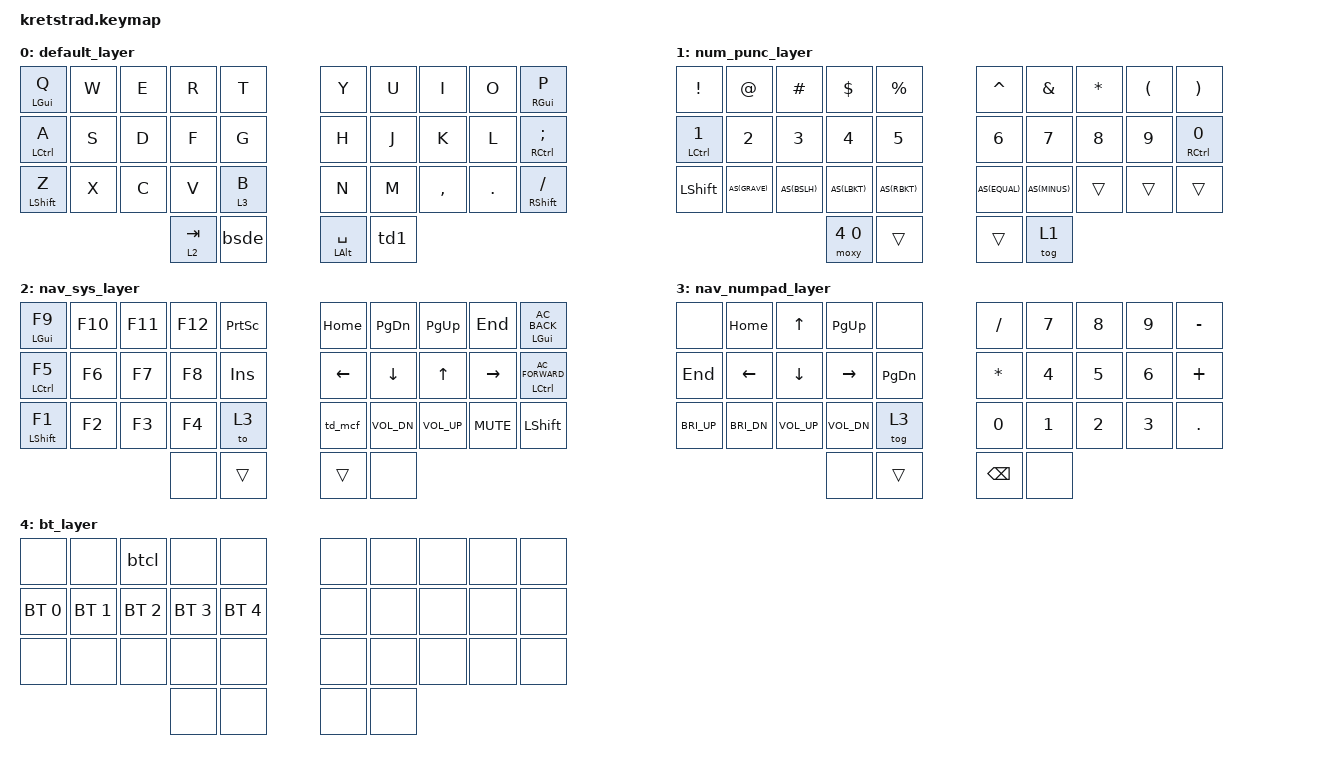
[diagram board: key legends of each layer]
/*
 * Copyright (c) 2020 The ZMK Contributors
 *
 * SPDX-License-Identifier: MIT
 */

#include <behaviors.dtsi>
#include <dt-bindings/zmk/keys.h>
#include <dt-bindings/zmk/bt.h>
#include <dt-bindings/zmk/mouse.h>

#define AS(keycode) &as keycode keycode     // Autoshift Macro
#define MB(keycode) &mbl keycode keycode    // Normal and sticky mouse key Macro

&sl {
    release-after-ms = <500>;
    /delete-property/ quick-release;
};

/ {

    macros {
        moxy: mo_to_x_back_to_y {
            compatible = "zmk,behavior-macro-two-param";
            #binding-cells = <2>;
            wait-ms = <0>;
            tap-ms = <0>;
            bindings
                = <&macro_param_1to1>
                , <&macro_press &mo MACRO_PLACEHOLDER>
                , <&macro_pause_for_release>
                , <&macro_param_1to1>
                , <&macro_release &mo MACRO_PLACEHOLDER>
                , <&macro_param_2to1>
                , <&macro_tap &to MACRO_PLACEHOLDER>
                ;
        };

        as_s: autoshift_single {
            compatible = "zmk,behavior-macro-one-param";
            #binding-cells = <1>;
            wait-ms = <0>;
            tap-ms = <0>;
            bindings
                = <&macro_press &kp LSHFT>
                , <&macro_param_1to1>
                , <&macro_tap &kp MACRO_PLACEHOLDER>
                , <&macro_release &kp LSHFT>
                ;
        };

    };

    behaviors {
        ht: hold_tap_standard {
            compatible = "zmk,behavior-hold-tap";
            #binding-cells = <2>;
            tapping-term-ms = <175>;
            quick-tap-ms = <250>;
            flavor = "tap-preferred";
            bindings = <&kp>, <&kp>;
        };

        hl: hold_tap_long {
            compatible = "zmk,behavior-hold-tap";
            #binding-cells = <2>;
            tapping-term-ms = <200>;
            quick-tap-ms = <250>;
            flavor = "tap-preferred";
            bindings = <&kp>, <&kp>;
        };

        hs: hold_tap_short {
            compatible = "zmk,behavior-hold-tap";
            #binding-cells = <2>;
            tapping-term-ms = <150>;
            quick-tap-ms = <250>;
            flavor = "tap-preferred";
            bindings = <&kp>, <&kp>;
        };

        hss: hold_tap_super_short {
            compatible = "zmk,behavior-hold-tap";
            #binding-cells = <2>;
            tapping-term-ms = <110>;
            quick-tap-ms = <250>;
            flavor = "tap-preferred";
            bindings = <&kp>, <&kp>;
        };

        pk: hold_tap_pinky {
            compatible = "zmk,behavior-hold-tap";
            #binding-cells = <2>;
            tapping-term-ms = <125>;
            quick-tap-ms = <250>;
            flavor = "tap-preferred";
            bindings = <&kp>, <&kp>;
        };

        mbl: mouse_button_long_press  {
            compatible = "zmk,behavior-hold-tap";
            #binding-cells = <2>;
            tapping_term_ms = <500>;
            flavor = "tap-preferred";
            bindings = <&skmk>, <&mkp>;
        };

        as: auto_shift_key  {
            compatible = "zmk,behavior-hold-tap";
            #binding-cells = <2>;
            tapping_term_ms = <225>;
            flavor = "tap-preferred";
            bindings = <&as_s>, <&kp>;
        };

        lh: layer_tap_hold_pref {
            compatible = "zmk,behavior-hold-tap";
            #binding-cells = <2>;
            tapping_term_ms = <150>;
            flavor = "hold-preferred";
            bindings = <&mo>, <&kp>;
        };

        bsde: backspace_delete {
            compatible = "zmk,behavior-mod-morph";
            #binding-cells = <0>;
            bindings = <&hss LALT BSPC>, <&kp DELETE>;
            mods = <(MOD_LSFT|MOD_RSFT)>;
            /* keep-mods = <(MOD_RSFT)>; */
        };

        td1: tap_dance_layer_1 {
            compatible = "zmk,behavior-tap-dance";
            #binding-cells = <0>;
            tapping-term-ms = <250>;
            bindings = <&sl 1>, <&to 1>;
        };

        td_mc: tap_dance_media_control {
            compatible = "zmk,behavior-tap-dance";
            #binding-cells = <0>;
            tapping-term-ms = <250>;
            bindings = <&kp C_NEXT>, <&kp C_PREV>;
        };

        td_mcf: tap_dance_media_control_full {
            compatible = "zmk,behavior-tap-dance";
            #binding-cells = <0>;
            tapping-term-ms = <250>;
            bindings = <&kp C_PP>, <&kp C_NEXT>, <&kp C_PREV>;
        };

        btcl: bluetooth_clear_double_tap {
            compatible = "zmk,behavior-tap-dance";
            #binding-cells = <0>;
            tapping-term-ms = <250>;
            bindings = <&none>, <&bt BT_CLR>;
        };

        skmk: sticky_mouse_key {
            compatible = "zmk,behavior-sticky-key";
            #binding-cells = <1>;
            bindings = <&mkp>;
            release-after-ms = <5000>;
            quick-release;
        };

    };

    keymap {
        compatible = "zmk,keymap";

        default_layer {
            bindings = <
                &hl LGUI Q   &kp W  &kp E  &kp R      &kp T        &kp Y            &kp U  &kp I      &kp O    &ht RGUI P
                &hl LCTRL A  &kp S  &kp D  &kp F      &kp G        &kp H            &kp J  &kp K      &kp L    &ht RCTRL SEMI
                &pk LSHFT Z  &kp X  &kp C  &kp V      &lt 3 B      &kp N            &kp M  &kp COMMA  &kp DOT  &pk RSHFT FSLH
                                           &lh 2 TAB  &bsde        &hs LALT SPACE   &td1
                >;
        };

        // Numbers and punctuations each on separate row
        num_punc_layer {
            bindings = <
                &kp EXCL      &kp AT     &kp HASH  &kp DLLR   &kp PRCNT      &kp CARET  &kp AMPS   &kp STAR  &kp LPAR  &kp RPAR
                &hl LCTRL N1  &kp N2     &kp N3    &kp N4     &kp N5         &kp N6     &kp N7     &kp N8    &kp N9    &ht RCTRL N0
                &kp LSHFT     AS(GRAVE)  AS(BSLH)  AS(LBKT)   AS(RBKT)       AS(EQUAL)  AS(MINUS)  &trans    &trans    &trans
                                                   &moxy 4 0  &trans         &trans     &tog 1
                >;
        };

        nav_sys_layer {
            bindings = <
                &ht LGUI F9   &kp F10  &kp F11  &kp F12  &kp PSCRN      &kp HOME  &kp PG_DN     &kp PG_UP     &kp END     &ht LGUI C_AC_BACK
                &ht LCTRL F5  &kp F6   &kp F7   &kp F8   &kp INS        &kp LEFT  &kp DOWN      &kp UP        &kp RIGHT   &ht LCTRL C_AC_FORWARD
                &ht LSHFT F1  &kp F2   &kp F3   &kp F4   &to 3          &td_mcf   &kp C_VOL_DN  &kp C_VOL_UP  &kp C_MUTE  &kp LSHFT
                                                &none    &trans         &trans    &none
                >;
        };

        nav_numpad_layer {
            bindings = <
                &none         &kp HOME     &kp UP        &kp PG_UP     &none          &kp FSLH  &kp N7  &kp N8  &kp N9  &kp MINUS
                &kp END       &kp LEFT     &kp DOWN      &kp RIGHT     &kp PG_DN      &kp STAR  &kp N4  &kp N5  &kp N6  &kp PLUS
                &kp C_BRI_UP  &kp C_BRI_DN &kp C_VOL_UP  &kp C_VOL_DN  &tog 3         &kp N0    &kp N1  &kp N2  &kp N3  &kp DOT
                                                         &none         &trans         &kp BSPC  &none
                >;
        };

        bt_layer {
            bindings = <
                &none         &none         &btcl         &none         &none             &none   &none   &none  &none  &none
                &bt BT_SEL 0  &bt BT_SEL 1  &bt BT_SEL 2  &bt BT_SEL 3  &bt BT_SEL 4      &none   &none   &none  &none  &none
                &none         &none         &none         &none         &none             &none   &none   &none  &none  &none
                                                          &none         &none             &none   &none
                >;
        };

    };

    combos {
        compatible = "zmk,combos";

        // Punctuation
        combo_equal {
            timeout-ms = <50>;
            key-positions = <0 1>;
            layers = <0 1>;
            bindings = <&kp EQUAL>;
        };

        combo_plus {
            timeout-ms = <50>;
            slow-release;
            key-positions = <1 12>;
            layers = <0 1>;
            bindings = <&kp PLUS>;
        };

        combo_under_score {
            timeout-ms = <50>;
            slow-release;
            key-positions = <8 17>;
            layers = <0 1>;
            bindings = <&kp UNDER>;
        };

        combo_minus {
            timeout-ms = <50>;
            key-positions = <8 9>;
            layers = <0 1>;
            bindings = <&kp MINUS>;
        };

        combo_left_bracket {
            timeout-ms = <50>;
            slow-release;
            key-positions = <2 13>;
            layers = <0>;
            bindings = <&kp LBKT>;
        };

        combo_left_brace {
            timeout-ms = <50>;
            slow-release;
            key-positions = <3 14>;
            layers = <0>;
            bindings = <&kp LBRC>;
        };

        combo_right_brace {
            timeout-ms = <50>;
            slow-release;
            key-positions = <6 15>;
            layers = <0>;
            bindings = <&kp RBRC>;
        };

        combo_right_bracket {
            timeout-ms = <50>;
            slow-release;
            key-positions = <7 16>;
            layers = <0>;
            bindings = <&kp RBKT>;
        };

        combo_tilde {
            timeout-ms = <50>;
            key-positions = <20 21>;
            layers = <0>;
            bindings = <&kp TILDE>;
        };

        combo_grave {
            timeout-ms = <50>;
            key-positions = <21 22>;
            layers = <0>;
            bindings = <&kp GRAVE>;
        };

        combo_back_slash {
            timeout-ms = <50>;
            key-positions = <27 28>;
            layers = <0>;
            bindings = <&kp BSLH>;
        };

        combo_pipe {
            timeout-ms = <50>;
            key-positions = <28 29>;
            layers = <0>;
            bindings = <&kp PIPE>;
        };

        combo_single_quote {
            timeout-ms = <50>;
            key-positions = <7 8>;
            layers = <0>;
            bindings = <&kp SQT>;
        };

        combo_double_quote {
            timeout-ms = <50>;
            key-positions = <18 19>;
            layers = <0>;
            bindings = <&kp DQT>;
        };


        // Control
        combo_enter {
            timeout-ms = <50>;
            key-positions = <17 18>;
            layers = <0 1 3>;
            bindings = <&kp ENTER>;
        };

        combo_caps {
            timeout-ms = <50>;
            slow-release;
            key-positions = <11 12>;
            layers = <0>;
            bindings = <&kp CAPS>;
        };

        combo_esc {
            timeout-ms = <50>;
            key-positions = <1 2>;
            layers = <0 1 2 3>;
            bindings = <&kp ESC>;
        };

        combo_esc_clear {
            timeout-ms = <50>;
            key-positions = <7 8>;
            layers = <3>;
            bindings = <&kp ESC>;
        };

        combo_mcf {
            timeout-ms = <50>;
            key-positions = <32 33>;
            layers = <0>;
            bindings = <&td_mcf>;
        };

        combo_L2 {
            timeout-ms = <50>;
            key-positions = <16 17 18>;
            layers = <0 2>;
            bindings = <&tog 2>;
        };

        combo_L3 {
            timeout-ms = <50>;
            /* key-positions = <11 12 13>; */
            key-positions = <26 27 28>;
            layers = <0 3>;
            bindings = <&tog 3>;
        };

    };

};

